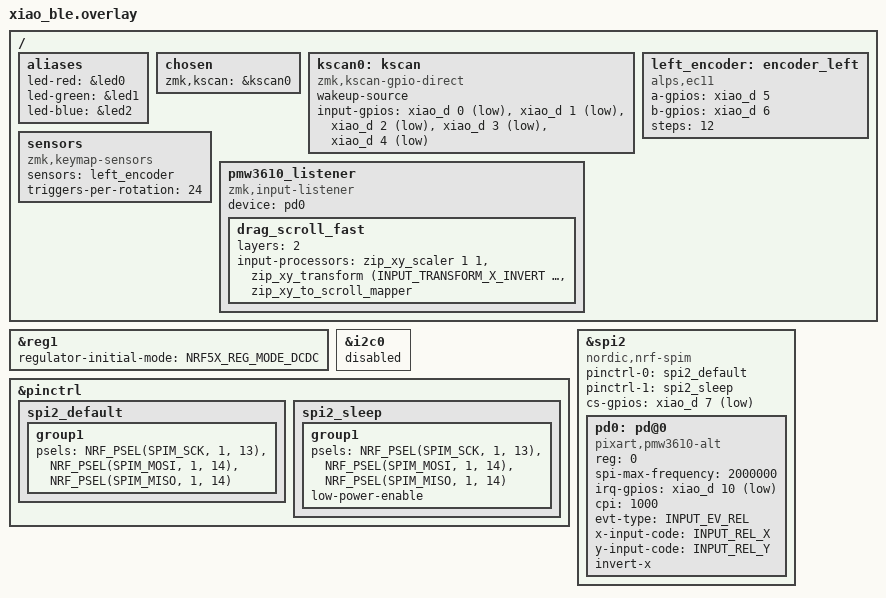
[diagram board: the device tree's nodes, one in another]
#include <dt-bindings/zmk/matrix_transform.h>
#include <zephyr/dt-bindings/input/input-event-codes.h>
#include <input/processors.dtsi>
#include <dt-bindings/zmk/input_transform.h>
#include <zephyr/dt-bindings/regulator/nrf5x.h>

/ {
    aliases {
        led-red = &led0;
        led-green = &led1;
        led-blue = &led2;
    };

    chosen {
        zmk,kscan = &kscan0;
    };

    kscan0: kscan {
        compatible = "zmk,kscan-gpio-direct";
        wakeup-source;
        input-gpios
            = <&xiao_d 0 (GPIO_ACTIVE_LOW | GPIO_PULL_UP)>
            , <&xiao_d 1 (GPIO_ACTIVE_LOW | GPIO_PULL_UP)>
            , <&xiao_d 2 (GPIO_ACTIVE_LOW | GPIO_PULL_UP)>
            , <&xiao_d 3 (GPIO_ACTIVE_LOW | GPIO_PULL_UP)>
            , <&xiao_d 4 (GPIO_ACTIVE_LOW | GPIO_PULL_UP)>
            ;
    };

    left_encoder: encoder_left {
        compatible = "alps,ec11";
        a-gpios = <&xiao_d 5 GPIO_ACTIVE_HIGH>;
        b-gpios = <&xiao_d 6 GPIO_ACTIVE_HIGH>;
        steps = <12>;
        status = "okay";
    };

    sensors: sensors {
        compatible = "zmk,keymap-sensors";
        sensors = <&left_encoder>;
        triggers-per-rotation = <24>;
    };

    pmw3610_listener {
        compatible = "zmk,input-listener";
        device = <&pd0>;

        drag_scroll_fast {
            layers = <2>;
            input-processors = <&zip_xy_scaler 1 1>, <&zip_xy_transform (INPUT_TRANSFORM_X_INVERT | INPUT_TRANSFORM_Y_INVERT)>, <&zip_xy_to_scroll_mapper>;
        };
    };
};

&reg1 {
    regulator-initial-mode = <NRF5X_REG_MODE_DCDC>;
};

&i2c0 {
    status = "disabled";
};

&pinctrl {
    spi2_default: spi2_default {
        group1 {
            psels = <NRF_PSEL(SPIM_SCK, 1, 13)>,
                    <NRF_PSEL(SPIM_MOSI, 1, 14)>,
                    <NRF_PSEL(SPIM_MISO, 1, 14)>;
        };
    };

    spi2_sleep: spi2_sleep {
        group1 {
            psels = <NRF_PSEL(SPIM_SCK, 1, 13)>,
                    <NRF_PSEL(SPIM_MOSI, 1, 14)>,
                    <NRF_PSEL(SPIM_MISO, 1, 14)>;
            low-power-enable;
        };
    };
};

&spi2 {
    compatible = "nordic,nrf-spim";
    status = "okay";
    pinctrl-0 = <&spi2_default>;
    pinctrl-1 = <&spi2_sleep>;
    pinctrl-names = "default", "sleep";
    cs-gpios = <&xiao_d 7 GPIO_ACTIVE_LOW>;

    pd0: pd@0 {
        compatible = "pixart,pmw3610-alt";
        status = "okay";
        reg = <0>;
        spi-max-frequency = <2000000>;
        irq-gpios = <&xiao_d 10 (GPIO_ACTIVE_LOW | GPIO_PULL_UP)>;
        cpi = <1000>;
        evt-type = <INPUT_EV_REL>;
        x-input-code = <INPUT_REL_X>;
        y-input-code = <INPUT_REL_Y>;
        invert-x;
    };
};
